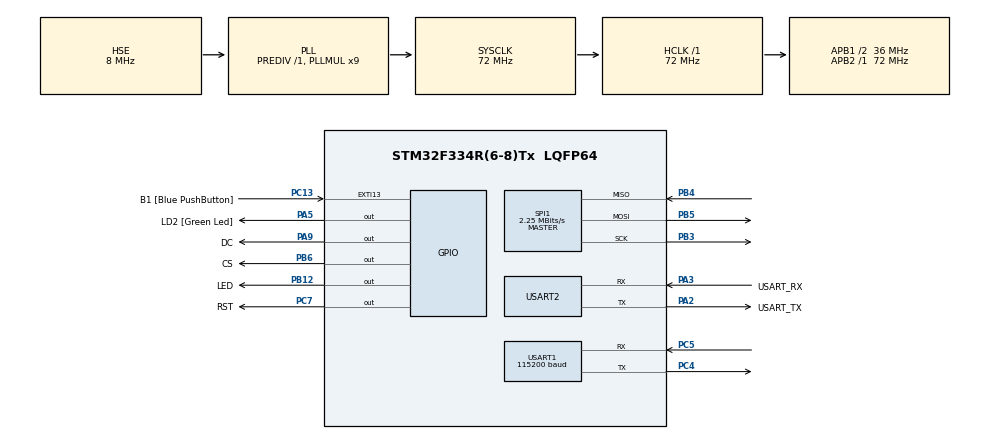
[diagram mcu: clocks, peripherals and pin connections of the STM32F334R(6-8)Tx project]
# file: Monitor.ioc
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Mcu.Family=STM32F3
Mcu.Name=STM32F334R(6-8)Tx
Mcu.Package=LQFP64
NVIC.EXTI15_10_IRQn=true\:0\:0\:false\:false\:true\:true\:true\:true
NVIC.PriorityGroup=NVIC_PRIORITYGROUP_4
NVIC.TIM1_UP_TIM16_IRQn=true\:0\:0\:false\:false\:true\:false\:true\:true
NVIC.TimeBase=TIM1_UP_TIM16_IRQn
NVIC.TimeBaseIP=TIM1
PA13.GPIO_Label=TMS
PA13.Mode=Serial_Wire
PA13.Signal=SYS_JTMS-SWDIO
PA14.GPIO_Label=TCK
PA14.Mode=Serial_Wire
PA14.Signal=SYS_JTCK-SWCLK
PA2.GPIO_Label=USART_TX
PA2.Mode=Asynchronous
PA2.Signal=USART2_TX
PA3.GPIO_Label=USART_RX
PA3.Mode=Asynchronous
PA3.Signal=USART2_RX
PA5.GPIO_Label=LD2 [Green Led]
PA5.Signal=GPIO_Output
PA9.GPIO_Label=DC
PA9.Signal=GPIO_Output
PB12.GPIO_Label=LED
PB12.Signal=GPIO_Output
PB3.Mode=Full_Duplex_Master
PB3.Signal=SPI1_SCK
PB4.Mode=Full_Duplex_Master
PB4.Signal=SPI1_MISO
PB5.Mode=Full_Duplex_Master
PB5.Signal=SPI1_MOSI
PB6.GPIO_Label=CS
PB6.Signal=GPIO_Output
PC13.GPIO_Label=B1 [Blue PushButton]
PC13.GPIO_ModeDefaultEXTI=GPIO_MODE_IT_FALLING
PC13.Signal=GPXTI13
PC14\ /\ OSC32_IN.Mode=LSE-External-Oscillator
PC14\ /\ OSC32_IN.Signal=RCC_OSC32_IN
PC15\ /\ OSC32_OUT.GPIO_Label=RCC_OSC32_OUT
PC15\ /\ OSC32_OUT.Mode=LSE-External-Oscillator
PC15\ /\ OSC32_OUT.Signal=RCC_OSC32_OUT
PC4.Mode=Asynchronous
PC4.Signal=USART1_TX
PC5.Mode=Asynchronous
PC5.Signal=USART1_RX
PC7.GPIO_Label=RST
PC7.Signal=GPIO_Output
PF0\ /\ OSC_IN.Mode=HSE-External-Clock-Source
PF0\ /\ OSC_IN.Signal=RCC_OSC_IN
PF1\ /\ OSC_OUT.Signal=RCC_OSC_OUT
ProjectManager.HeapSize=0x400
ProjectManager.StackSize=0x800
ProjectManager.TargetToolchain=Makefile
RCC.AHBFreq_Value=72000000
RCC.APB1CLKDivider=RCC_HCLK_DIV2
RCC.APB1Freq_Value=36000000
RCC.APB1TimFreq_Value=72000000
RCC.APB2Freq_Value=72000000
RCC.APB2TimFreq_Value=72000000
RCC.CortexFreq_Value=72000000
RCC.FLatency-AdvancedSettings=FLASH_LATENCY_2
RCC.HCLKFreq_Value=72000000
RCC.HSE_VALUE=8000000
RCC.HSI_VALUE=8000000
RCC.PLLMUL=RCC_PLL_MUL9
RCC.PLLSourceVirtual=RCC_PLLSOURCE_HSE
RCC.SYSCLKFreq_VALUE=72000000
RCC.SYSCLKSourceVirtual=RCC_SYSCLKSOURCE_PLLCLK
SPI1.BaudRatePrescaler=SPI_BAUDRATEPRESCALER_32
SPI1.CalculateBaudRate=2.25 MBits/s
SPI1.DataSize=SPI_DATASIZE_8BIT
SPI1.Direction=SPI_DIRECTION_2LINES
SPI1.Mode=SPI_MODE_MASTER
SPI1.VirtualType=VM_MASTER
USART1.BaudRate=115200
USART1.VirtualMode-Asynchronous=VM_ASYNC
USART2.VirtualMode-Asynchronous=VM_ASYNC
VP_SYS_VS_tim1.Mode=TIM1
board=NUCLEO-F334R8

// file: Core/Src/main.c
/* USER CODE BEGIN Header */
/**
  ******************************************************************************
  * @file           : main.c
  * @brief          : Main program body
  ******************************************************************************
  * @attention
  *
  * Copyright (c) 2022 STMicroelectronics.
  * All rights reserved.
  *
  * This software is licensed under terms that can be found in the LICENSE file
  * in the root directory of this software component.
  * If no LICENSE file comes with this software, it is provided AS-IS.
  *
  ******************************************************************************
  */
/* USER CODE END Header */
#include "main.h"

/* USER CODE BEGIN Includes */
#include "ILI9341.h"
#include "display.h"
#include "User.h"
/* USER CODE END Includes */

 SPI_HandleTypeDef hspi1;

UART_HandleTypeDef huart1;
UART_HandleTypeDef huart2;

void SystemClock_Config(void);
static void MX_GPIO_Init(void);
static void MX_SPI1_Init(void);
static void MX_USART2_UART_Init(void);
static void MX_USART1_UART_Init(void);

int main(void)
{

  /* MCU Configuration--------------------------------------------------------*/

  /* Reset of all peripherals, Initializes the Flash interface and the Systick. */
  HAL_Init();

  /* Configure the system clock */
  SystemClock_Config();

  /* Initialize all configured peripherals */
  MX_GPIO_Init();
  MX_SPI1_Init();
  MX_USART2_UART_Init();
  MX_USART1_UART_Init();
  /* USER CODE BEGIN 2 */

  HAL_GPIO_WritePin(GPIOB, LED_Pin, GPIO_PIN_SET);
  ILI9341_Init();

  Display_Text();

  /* USER CODE END 2 */

  /* Infinite loop */
  while (1)
  {
    User_Display();
  }
}

void SystemClock_Config(void)
{
  RCC_OscInitTypeDef RCC_OscInitStruct = {0};
  RCC_ClkInitTypeDef RCC_ClkInitStruct = {0};
  RCC_PeriphCLKInitTypeDef PeriphClkInit = {0};

  /** Initializes the RCC Oscillators according to the specified parameters
  * in the RCC_OscInitTypeDef structure.
  */
  RCC_OscInitStruct.OscillatorType = RCC_OSCILLATORTYPE_HSE;
  RCC_OscInitStruct.HSEState = RCC_HSE_BYPASS;
  RCC_OscInitStruct.HSEPredivValue = RCC_HSE_PREDIV_DIV1;
  RCC_OscInitStruct.HSIState = RCC_HSI_ON;
  RCC_OscInitStruct.PLL.PLLState = RCC_PLL_ON;
  RCC_OscInitStruct.PLL.PLLSource = RCC_PLLSOURCE_HSE;
  RCC_OscInitStruct.PLL.PLLMUL = RCC_PLL_MUL9;
  if (HAL_RCC_OscConfig(&RCC_OscInitStruct) != HAL_OK)
  {
    Error_Handler();
  }

  /** Initializes the CPU, AHB and APB buses clocks
  */
  RCC_ClkInitStruct.ClockType = RCC_CLOCKTYPE_HCLK|RCC_CLOCKTYPE_SYSCLK
                              |RCC_CLOCKTYPE_PCLK1|RCC_CLOCKTYPE_PCLK2;
  RCC_ClkInitStruct.SYSCLKSource = RCC_SYSCLKSOURCE_PLLCLK;
  RCC_ClkInitStruct.AHBCLKDivider = RCC_SYSCLK_DIV1;
  RCC_ClkInitStruct.APB1CLKDivider = RCC_HCLK_DIV2;
  RCC_ClkInitStruct.APB2CLKDivider = RCC_HCLK_DIV1;

  if (HAL_RCC_ClockConfig(&RCC_ClkInitStruct, FLASH_LATENCY_2) != HAL_OK)
  {
    Error_Handler();
  }
  PeriphClkInit.PeriphClockSelection = RCC_PERIPHCLK_USART1;
  PeriphClkInit.Usart1ClockSelection = RCC_USART1CLKSOURCE_PCLK1;
  if (HAL_RCCEx_PeriphCLKConfig(&PeriphClkInit) != HAL_OK)
  {
    Error_Handler();
  }
}

static void MX_SPI1_Init(void)
{

  /* SPI1 parameter configuration*/
  hspi1.Instance = SPI1;
  hspi1.Init.Mode = SPI_MODE_MASTER;
  hspi1.Init.Direction = SPI_DIRECTION_2LINES;
  hspi1.Init.DataSize = SPI_DATASIZE_8BIT;
  hspi1.Init.CLKPolarity = SPI_POLARITY_LOW;
  hspi1.Init.CLKPhase = SPI_PHASE_1EDGE;
  hspi1.Init.NSS = SPI_NSS_SOFT;
  hspi1.Init.BaudRatePrescaler = SPI_BAUDRATEPRESCALER_32;
  hspi1.Init.FirstBit = SPI_FIRSTBIT_MSB;
  hspi1.Init.TIMode = SPI_TIMODE_DISABLE;
  hspi1.Init.CRCCalculation = SPI_CRCCALCULATION_DISABLE;
  hspi1.Init.CRCPolynomial = 7;
  hspi1.Init.CRCLength = SPI_CRC_LENGTH_DATASIZE;
  hspi1.Init.NSSPMode = SPI_NSS_PULSE_ENABLE;
  if (HAL_SPI_Init(&hspi1) != HAL_OK)
  {
    Error_Handler();
  }

}

static void MX_USART1_UART_Init(void)
{

  huart1.Instance = USART1;
  huart1.Init.BaudRate = 115200;
  huart1.Init.WordLength = UART_WORDLENGTH_8B;
  huart1.Init.StopBits = UART_STOPBITS_1;
  huart1.Init.Parity = UART_PARITY_NONE;
  huart1.Init.Mode = UART_MODE_TX_RX;
  huart1.Init.HwFlowCtl = UART_HWCONTROL_NONE;
  huart1.Init.OverSampling = UART_OVERSAMPLING_16;
  huart1.Init.OneBitSampling = UART_ONE_BIT_SAMPLE_DISABLE;
  huart1.AdvancedInit.AdvFeatureInit = UART_ADVFEATURE_NO_INIT;
  if (HAL_UART_Init(&huart1) != HAL_OK)
  {
    Error_Handler();
  }

}

static void MX_USART2_UART_Init(void)
{

  huart2.Instance = USART2;
  huart2.Init.BaudRate = 38400;
  huart2.Init.WordLength = UART_WORDLENGTH_8B;
  huart2.Init.StopBits = UART_STOPBITS_1;
  huart2.Init.Parity = UART_PARITY_NONE;
  huart2.Init.Mode = UART_MODE_TX_RX;
  huart2.Init.HwFlowCtl = UART_HWCONTROL_NONE;
  huart2.Init.OverSampling = UART_OVERSAMPLING_16;
  huart2.Init.OneBitSampling = UART_ONE_BIT_SAMPLE_DISABLE;
  huart2.AdvancedInit.AdvFeatureInit = UART_ADVFEATURE_NO_INIT;
  if (HAL_UART_Init(&huart2) != HAL_OK)
  {
    Error_Handler();
  }

}

static void MX_GPIO_Init(void)
{
  GPIO_InitTypeDef GPIO_InitStruct = {0};

  /* GPIO Ports Clock Enable */
  __HAL_RCC_GPIOC_CLK_ENABLE();
  __HAL_RCC_GPIOF_CLK_ENABLE();
  __HAL_RCC_GPIOA_CLK_ENABLE();
  __HAL_RCC_GPIOB_CLK_ENABLE();

  /*Configure GPIO pin Output Level */
  HAL_GPIO_WritePin(GPIOA, LD2_Pin|DC_Pin, GPIO_PIN_RESET);

  /*Configure GPIO pin Output Level */
  HAL_GPIO_WritePin(GPIOB, LED_Pin|CS_Pin, GPIO_PIN_RESET);

  /*Configure GPIO pin Output Level */
  HAL_GPIO_WritePin(RST_GPIO_Port, RST_Pin, GPIO_PIN_RESET);

  /*Configure GPIO pin : B1_Pin */
  GPIO_InitStruct.Pin = B1_Pin;
  GPIO_InitStruct.Mode = GPIO_MODE_IT_FALLING;
  GPIO_InitStruct.Pull = GPIO_NOPULL;
  HAL_GPIO_Init(B1_GPIO_Port, &GPIO_InitStruct);

  /*Configure GPIO pins : LD2_Pin DC_Pin */
  GPIO_InitStruct.Pin = LD2_Pin|DC_Pin;
  GPIO_InitStruct.Mode = GPIO_MODE_OUTPUT_PP;
  GPIO_InitStruct.Pull = GPIO_NOPULL;
  GPIO_InitStruct.Speed = GPIO_SPEED_FREQ_LOW;
  HAL_GPIO_Init(GPIOA, &GPIO_InitStruct);

  /*Configure GPIO pins : LED_Pin CS_Pin */
  GPIO_InitStruct.Pin = LED_Pin|CS_Pin;
  GPIO_InitStruct.Mode = GPIO_MODE_OUTPUT_PP;
  GPIO_InitStruct.Pull = GPIO_NOPULL;
  GPIO_InitStruct.Speed = GPIO_SPEED_FREQ_LOW;
  HAL_GPIO_Init(GPIOB, &GPIO_InitStruct);

  /*Configure GPIO pin : RST_Pin */
  GPIO_InitStruct.Pin = RST_Pin;
  GPIO_InitStruct.Mode = GPIO_MODE_OUTPUT_PP;
  GPIO_InitStruct.Pull = GPIO_NOPULL;
  GPIO_InitStruct.Speed = GPIO_SPEED_FREQ_LOW;
  HAL_GPIO_Init(RST_GPIO_Port, &GPIO_InitStruct);

  /* EXTI interrupt init*/
  HAL_NVIC_SetPriority(EXTI15_10_IRQn, 0, 0);
  HAL_NVIC_EnableIRQ(EXTI15_10_IRQn);

}

void HAL_TIM_PeriodElapsedCallback(TIM_HandleTypeDef *htim)
{
  if (htim->Instance == TIM1) {
    HAL_IncTick();
  }
}

void Error_Handler(void)
{
  __disable_irq();
  while (1)
  {
  }
}
